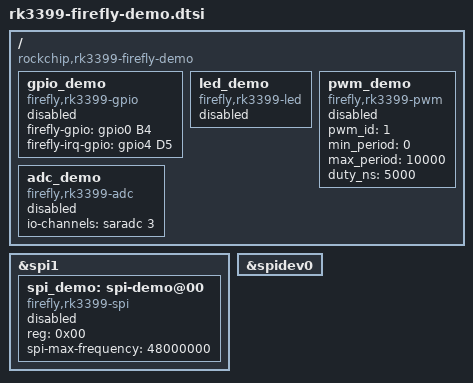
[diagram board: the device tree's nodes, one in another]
/*
 * Copyright (c) 2016 Fuzhou Rockchip Electronics Co., Ltd
 *
 * This file is dual-licensed: you can use it either under the terms
 * of the GPL or the X11 license, at your option. Note that this dual
 * licensing only applies to this file, and not this project as a
 * whole.
 *
 *  a) This file is free software; you can redistribute it and/or
 *     modify it under the terms of the GNU General Public License as
 *     published by the Free Software Foundation; either version 2 of the
 *     License, or (at your option) any later version.
 *
 *     This file is distributed in the hope that it will be useful,
 *     but WITHOUT ANY WARRANTY; without even the implied warranty of
 *     MERCHANTABILITY or FITNESS FOR A PARTICULAR PURPOSE.  See the
 *     GNU General Public License for more details.
 *
 * Or, alternatively,
 *
 *  b) Permission is hereby granted, free of charge, to any person
 *     obtaining a copy of this software and associated documentation
 *     files (the "Software"), to deal in the Software without
 *     restriction, including without limitation the rights to use,
 *     copy, modify, merge, publish, distribute, sublicense, and/or
 *     sell copies of the Software, and to permit persons to whom the
 *     Software is furnished to do so, subject to the following
 *     conditions:
 *
 *     The above copyright notice and this permission notice shall be
 *     included in all copies or substantial portions of the Software.
 *
 *     THE SOFTWARE IS PROVIDED "AS IS", WITHOUT WARRANTY OF ANY KIND,
 *     EXPRESS OR IMPLIED, INCLUDING BUT NOT LIMITED TO THE WARRANTIES
 *     OF MERCHANTABILITY, FITNESS FOR A PARTICULAR PURPOSE AND
 *     NONINFRINGEMENT. IN NO EVENT SHALL THE AUTHORS OR COPYRIGHT
 *     HOLDERS BE LIABLE FOR ANY CLAIM, DAMAGES OR OTHER LIABILITY,
 *     WHETHER IN AN ACTION OF CONTRACT, TORT OR OTHERWISE, ARISING
 *     FROM, OUT OF OR IN CONNECTION WITH THE SOFTWARE OR THE USE OR
 *     OTHER DEALINGS IN THE SOFTWARE.
 */


/ {
	compatible = "rockchip,rk3399-firefly-demo", "rockchip,rk3399";

	gpio_demo: gpio_demo {
	    status = "disabled";
	    compatible = "firefly,rk3399-gpio";
	    firefly-gpio = <&gpio0 B4 GPIO_ACTIVE_HIGH>;          /* GPIO0_B4 */
	    firefly-irq-gpio = <&gpio4 D5 IRQ_TYPE_EDGE_RISING>;  /* GPIO4_D5 */
	};
	
	    led_demo: led_demo {
                status = "disabled";
                compatible = "firefly,rk3399-led";
        };

        pwm_demo: pwm_demo {
                status = "disabled";
                compatible = "firefly,rk3399-pwm";
                pwm_id = <1>;
                min_period = <0>;
                max_period = <10000>;
                duty_ns = <5000>;
        };
    adc_demo: adc_demo{
        status = "disabled";
        compatible = "firefly,rk3399-adc";
        io-channels = <&saradc 3>;

    };
};

/* Firefly SPI demo */
&spi1 {
	spi_demo: spi-demo@00{
		status = "disabled";
		compatible = "firefly,rk3399-spi";
		reg = <0x00>;
		spi-max-frequency = <48000000>;
		/* rk3399 driver support SPI_CPOL | SPI_CPHA | SPI_CS_HIGH */
		//spi-cpha;		/* SPI mode: CPHA=1 */
		//spi-cpol;   	/* SPI mode: CPOL=1 */
		//spi-cs-high;
	};
};

&spidev0 {
	status = "okay";
};

